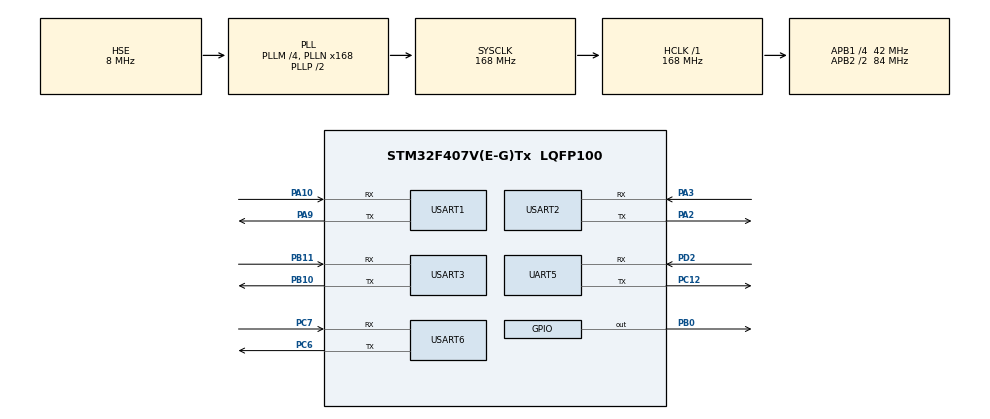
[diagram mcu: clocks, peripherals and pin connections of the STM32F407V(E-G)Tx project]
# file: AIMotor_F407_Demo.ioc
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Dma.Request0=USART1_RX
Dma.Request1=USART2_RX
Dma.Request2=USART3_RX
Dma.Request3=UART5_RX
Dma.Request4=USART6_RX
Dma.UART5_RX.3.Direction=DMA_PERIPH_TO_MEMORY
Dma.UART5_RX.3.FIFOMode=DMA_FIFOMODE_DISABLE
Dma.UART5_RX.3.Instance=DMA1_Stream0
Dma.UART5_RX.3.MemDataAlignment=DMA_MDATAALIGN_BYTE
Dma.UART5_RX.3.MemInc=DMA_MINC_ENABLE
Dma.UART5_RX.3.Mode=DMA_NORMAL
Dma.UART5_RX.3.PeriphDataAlignment=DMA_PDATAALIGN_BYTE
Dma.UART5_RX.3.PeriphInc=DMA_PINC_DISABLE
Dma.UART5_RX.3.Priority=DMA_PRIORITY_LOW
Dma.USART1_RX.0.Direction=DMA_PERIPH_TO_MEMORY
Dma.USART1_RX.0.FIFOMode=DMA_FIFOMODE_DISABLE
Dma.USART1_RX.0.Instance=DMA2_Stream2
Dma.USART1_RX.0.MemDataAlignment=DMA_MDATAALIGN_BYTE
Dma.USART1_RX.0.MemInc=DMA_MINC_ENABLE
Dma.USART1_RX.0.Mode=DMA_NORMAL
Dma.USART1_RX.0.PeriphDataAlignment=DMA_PDATAALIGN_BYTE
Dma.USART1_RX.0.PeriphInc=DMA_PINC_DISABLE
Dma.USART1_RX.0.Priority=DMA_PRIORITY_LOW
Dma.USART2_RX.1.Direction=DMA_PERIPH_TO_MEMORY
Dma.USART2_RX.1.FIFOMode=DMA_FIFOMODE_DISABLE
Dma.USART2_RX.1.Instance=DMA1_Stream5
Dma.USART2_RX.1.MemDataAlignment=DMA_MDATAALIGN_BYTE
Dma.USART2_RX.1.MemInc=DMA_MINC_ENABLE
Dma.USART2_RX.1.Mode=DMA_NORMAL
Dma.USART2_RX.1.PeriphDataAlignment=DMA_PDATAALIGN_BYTE
Dma.USART2_RX.1.PeriphInc=DMA_PINC_DISABLE
Dma.USART2_RX.1.Priority=DMA_PRIORITY_LOW
Dma.USART3_RX.2.Direction=DMA_PERIPH_TO_MEMORY
Dma.USART3_RX.2.FIFOMode=DMA_FIFOMODE_DISABLE
Dma.USART3_RX.2.Instance=DMA1_Stream1
Dma.USART3_RX.2.MemDataAlignment=DMA_MDATAALIGN_BYTE
Dma.USART3_RX.2.MemInc=DMA_MINC_ENABLE
Dma.USART3_RX.2.Mode=DMA_NORMAL
Dma.USART3_RX.2.PeriphDataAlignment=DMA_PDATAALIGN_BYTE
Dma.USART3_RX.2.PeriphInc=DMA_PINC_DISABLE
Dma.USART3_RX.2.Priority=DMA_PRIORITY_LOW
Dma.USART6_RX.4.Direction=DMA_PERIPH_TO_MEMORY
Dma.USART6_RX.4.FIFOMode=DMA_FIFOMODE_DISABLE
Dma.USART6_RX.4.Instance=DMA2_Stream1
Dma.USART6_RX.4.MemDataAlignment=DMA_MDATAALIGN_BYTE
Dma.USART6_RX.4.MemInc=DMA_MINC_ENABLE
Dma.USART6_RX.4.Mode=DMA_NORMAL
Dma.USART6_RX.4.PeriphDataAlignment=DMA_PDATAALIGN_BYTE
Dma.USART6_RX.4.PeriphInc=DMA_PINC_DISABLE
Dma.USART6_RX.4.Priority=DMA_PRIORITY_LOW
Mcu.Family=STM32F4
Mcu.Name=STM32F407V(E-G)Tx
Mcu.Package=LQFP100
NVIC.DMA1_Stream0_IRQn=true\:0\:0\:false\:false\:true\:false\:true\:true
NVIC.DMA1_Stream1_IRQn=true\:0\:0\:false\:false\:true\:false\:true\:true
NVIC.DMA1_Stream5_IRQn=true\:0\:0\:false\:false\:true\:false\:true\:true
NVIC.DMA2_Stream1_IRQn=true\:0\:0\:false\:false\:true\:false\:true\:true
NVIC.DMA2_Stream2_IRQn=true\:0\:0\:false\:false\:true\:false\:true\:true
NVIC.PriorityGroup=NVIC_PRIORITYGROUP_4
NVIC.UART5_IRQn=true\:0\:0\:false\:false\:true\:true\:true\:true
NVIC.USART1_IRQn=true\:0\:0\:false\:false\:true\:true\:true\:true
NVIC.USART2_IRQn=true\:0\:0\:false\:false\:true\:true\:true\:true
NVIC.USART3_IRQn=true\:0\:0\:false\:false\:true\:true\:true\:true
NVIC.USART6_IRQn=true\:0\:0\:false\:false\:true\:true\:true\:true
PA10.Mode=Asynchronous
PA10.Signal=USART1_RX
PA13.Mode=Serial_Wire
PA13.Signal=SYS_JTMS-SWDIO
PA14.Mode=Serial_Wire
PA14.Signal=SYS_JTCK-SWCLK
PA2.Mode=Asynchronous
PA2.Signal=USART2_TX
PA3.Mode=Asynchronous
PA3.Signal=USART2_RX
PA9.Mode=Asynchronous
PA9.Signal=USART1_TX
PB0.Signal=GPIO_Output
PB10.Mode=Asynchronous
PB10.Signal=USART3_TX
PB11.Mode=Asynchronous
PB11.Signal=USART3_RX
PC12.Mode=Asynchronous
PC12.Signal=UART5_TX
PC6.Mode=Asynchronous
PC6.Signal=USART6_TX
PC7.Mode=Asynchronous
PC7.Signal=USART6_RX
PD2.Mode=Asynchronous
PD2.Signal=UART5_RX
PH0-OSC_IN.Mode=HSE-External-Oscillator
PH0-OSC_IN.Signal=RCC_OSC_IN
PH1-OSC_OUT.Mode=HSE-External-Oscillator
PH1-OSC_OUT.Signal=RCC_OSC_OUT
ProjectManager.HeapSize=0x200
ProjectManager.StackSize=0x400
ProjectManager.TargetToolchain=MDK-ARM V5.32
RCC.48MHZClocksFreq_Value=84000000
RCC.AHBFreq_Value=168000000
RCC.APB1CLKDivider=RCC_HCLK_DIV4
RCC.APB1Freq_Value=42000000
RCC.APB1TimFreq_Value=84000000
RCC.APB2CLKDivider=RCC_HCLK_DIV2
RCC.APB2Freq_Value=84000000
RCC.APB2TimFreq_Value=168000000
RCC.CortexFreq_Value=168000000
RCC.HCLKFreq_Value=168000000
RCC.HSE_VALUE=8000000
RCC.HSI_VALUE=16000000
RCC.LSE_VALUE=32768
RCC.PLLM=4
RCC.PLLN=168
RCC.PLLSourceVirtual=RCC_PLLSOURCE_HSE
RCC.SYSCLKFreq_VALUE=168000000
RCC.SYSCLKSource=RCC_SYSCLKSOURCE_PLLCLK
RCC.VCOOutputFreq_Value=336000000
UART5.VirtualMode=Asynchronous
USART1.VirtualMode=VM_ASYNC
USART2.VirtualMode=VM_ASYNC
USART3.VirtualMode=VM_ASYNC
USART6.VirtualMode=VM_ASYNC
board=custom

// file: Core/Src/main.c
/* USER CODE BEGIN Header */
/**
  ******************************************************************************
  * @file           : main.c
  * @brief          : Main program body
  ******************************************************************************
  * @attention
  *
  * Copyright (c) 2026 STMicroelectronics.
  * All rights reserved.
  *
  * This software is licensed under terms that can be found in the LICENSE file
  * in the root directory of this software component.
  * If no LICENSE file comes with this software, it is provided AS-IS.
  *
  ******************************************************************************
  */
/* USER CODE END Header */
#include "main.h"
#include "dma.h"
#include "usart.h"
#include "gpio.h"

/* USER CODE BEGIN Includes */
#include "aimotor.h"
#include "mwmotor.h"
#include "host_protocol.h"
/* USER CODE END Includes */

/* USER CODE BEGIN PV */

/* 主循环节拍（5ms 调度）；上位机协议缓冲所有权已移至 App/Src/host_protocol.c */
static uint32_t aimotor_last_tick = 0;
static uint32_t mwmotor_last_tick = 0;

/* USER CODE END PV */

void SystemClock_Config(void);

/* USER CODE BEGIN 0 */
/* UART 回调分发已迁至 App/Src/comm_router.c */

/* USER CODE END 0 */

int main(void)
{

  /* MCU Configuration--------------------------------------------------------*/

  /* Reset of all peripherals, Initializes the Flash interface and the Systick. */
  HAL_Init();

  /* Configure the system clock */
  SystemClock_Config();

  /* Initialize all configured peripherals */
  MX_GPIO_Init();
  MX_DMA_Init();
  MX_USART1_UART_Init();
  MX_USART2_UART_Init();
  MX_USART3_UART_Init();
  MX_UART5_Init();
  MX_USART6_UART_Init();
  /* USER CODE BEGIN 2 */

		/* 初始化上位机协议层（USART1 DMA 空闲接收，实现在 App/Src/host_protocol.c） */
		Host_ProtocolInit();
		/* 初始化 AI 电机系统（USART2/USART3, Modbus RTU） */
		Aimotor_Init();
		/* 初始化慕纬度电机系统（USART6/UART5, 私有协议） */
		MW_Init();

#if AIMOTOR_SELF_TEST
		/* 固件自检：直接调用生产 C 函数（解析器/状态机/换算/STATE/看门狗），
		   输出逐项 PASS/FAIL 到 USART1。仅在 DRY_RUN=1 时允许。 */
		Aimotor_SelfTest();
#endif

  /* USER CODE END 2 */

  /* Infinite loop */
  while (1)
  {

    /* 两类电机状态机均按 5ms 调度；实际发送由“一次一帧、等待回包”限制。 */
    uint32_t now = HAL_GetTick();
    if (now - aimotor_last_tick >= AIMOTOR_TICK_MS) {
        aimotor_last_tick = now;
        Aimotor_Process();      /* 内含上位机流解析 */
        Aimotor_CommWatchdog(); /* 通信看门狗（无阻塞） */
    }

    /* J4/J5/J6独立使用5ms周期，缩短耦合轴命令间隔。 */
    if (now - mwmotor_last_tick >= MW_TICK_MS) {
        mwmotor_last_tick = now;
        MW_Process();
    }

  }
}

void SystemClock_Config(void)
{
  RCC_OscInitTypeDef RCC_OscInitStruct = {0};
  RCC_ClkInitTypeDef RCC_ClkInitStruct = {0};

  /** Configure the main internal regulator output voltage
  */
  __HAL_RCC_PWR_CLK_ENABLE();
  __HAL_PWR_VOLTAGESCALING_CONFIG(PWR_REGULATOR_VOLTAGE_SCALE1);

  /** Initializes the RCC Oscillators according to the specified parameters
  * in the RCC_OscInitTypeDef structure.
  */
  RCC_OscInitStruct.OscillatorType = RCC_OSCILLATORTYPE_HSE;
  RCC_OscInitStruct.HSEState = RCC_HSE_ON;
  RCC_OscInitStruct.PLL.PLLState = RCC_PLL_ON;
  RCC_OscInitStruct.PLL.PLLSource = RCC_PLLSOURCE_HSE;
  RCC_OscInitStruct.PLL.PLLM = 4;
  RCC_OscInitStruct.PLL.PLLN = 168;
  RCC_OscInitStruct.PLL.PLLP = RCC_PLLP_DIV2;
  RCC_OscInitStruct.PLL.PLLQ = 4;
  if (HAL_RCC_OscConfig(&RCC_OscInitStruct) != HAL_OK)
  {
    Error_Handler();
  }

  /** Initializes the CPU, AHB and APB buses clocks
  */
  RCC_ClkInitStruct.ClockType = RCC_CLOCKTYPE_HCLK|RCC_CLOCKTYPE_SYSCLK
                              |RCC_CLOCKTYPE_PCLK1|RCC_CLOCKTYPE_PCLK2;
  RCC_ClkInitStruct.SYSCLKSource = RCC_SYSCLKSOURCE_PLLCLK;
  RCC_ClkInitStruct.AHBCLKDivider = RCC_SYSCLK_DIV1;
  RCC_ClkInitStruct.APB1CLKDivider = RCC_HCLK_DIV4;
  RCC_ClkInitStruct.APB2CLKDivider = RCC_HCLK_DIV2;

  if (HAL_RCC_ClockConfig(&RCC_ClkInitStruct, FLASH_LATENCY_5) != HAL_OK)
  {
    Error_Handler();
  }
}

void Error_Handler(void)
{
  __disable_irq();
  while (1)
  {
  }
}
